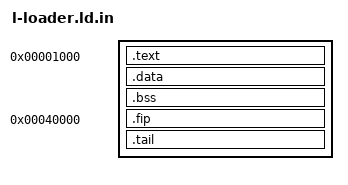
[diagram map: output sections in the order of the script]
/*
 * (C) Copyright 2017 Linaro Limited
 *
 * Jorge Ramirez-Ortiz <jorge.ramirez-ortiz@linaro.org>
 *
 * Configuration for Poplar 96boards EE. Parts were derived from other ARM
 * configurations.
 *
 * SPDX-License-Identifier:	GPL-2.0+
 *
 */

/*
 * LLOADER_TEXT_BASE must be page-aligned.  This is because we place
 * the ARM Trusted Firmware BL1 image at a page size multiple offset
 * from that address, and that image is required to be page aligned.
 */
#define LLOADER_TEXT_BASE	0x00001000

#define FIP_BASE		0x00040000

OUTPUT_FORMAT("elf32-littlearm", "elf32-littlearm", "elf32-littlearm")
OUTPUT_ARCH(arm)
ENTRY(start)
SECTIONS
{
	. = LLOADER_TEXT_BASE;
	.text	:
	{
		*(.text)
		*(.rodata)
	}

	. = ALIGN(4);
	.data : { *(.data) }

	. = ALIGN(4);
	.bss : { *(.bss) }

	. = FIP_BASE;
       .fip : { *(.fip) }

	. = ALIGN(4);
       .tail : { *(.tail) }
}
